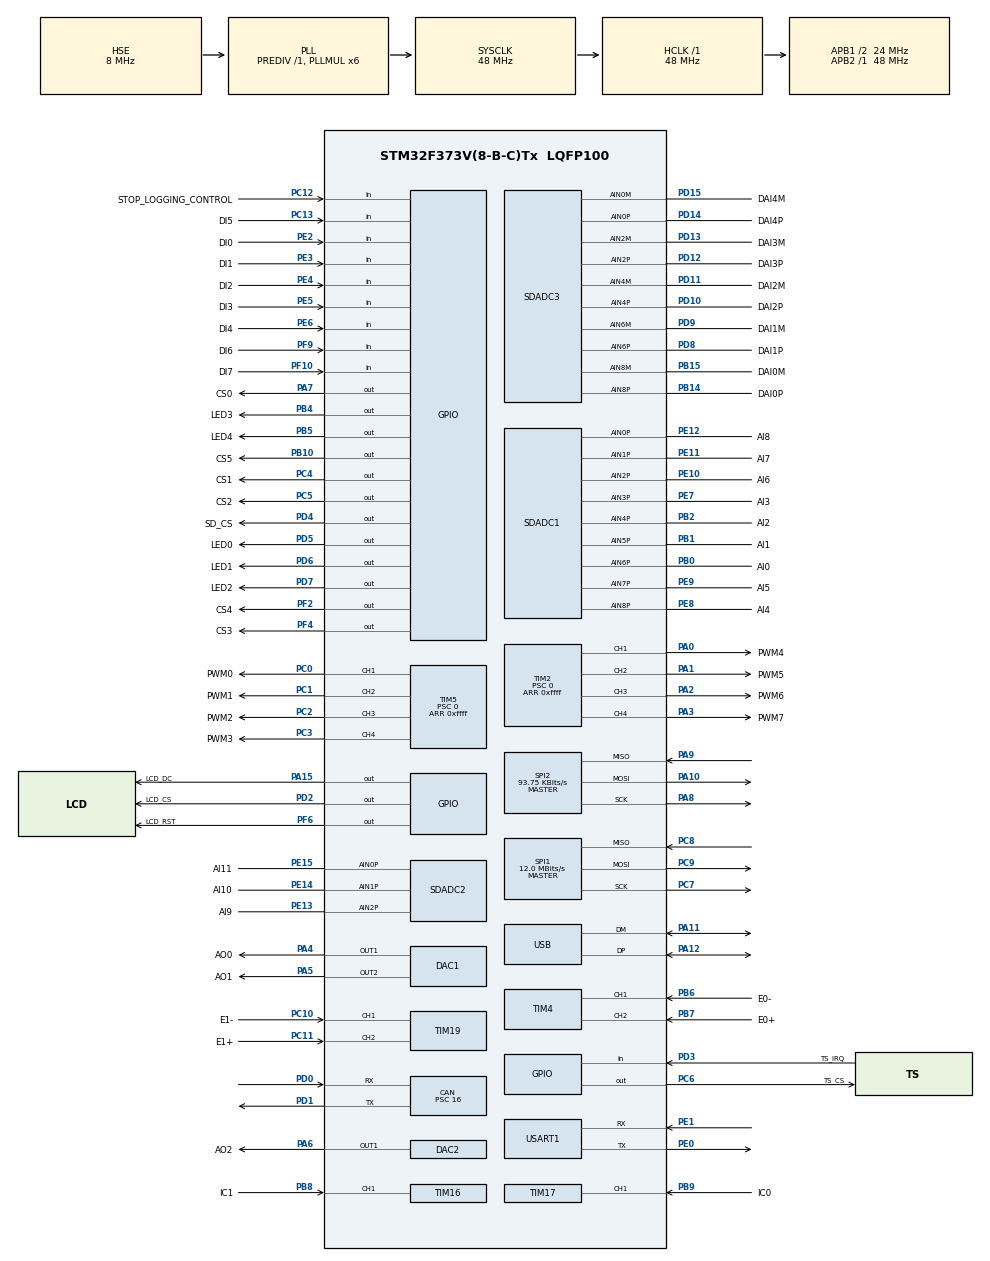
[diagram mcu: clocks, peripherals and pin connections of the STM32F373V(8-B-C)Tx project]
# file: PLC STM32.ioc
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CAN.BS1=CAN_BS1_3TQ
CAN.BS2=CAN_BS2_2TQ
CAN.CalculateBaudRate=250000
CAN.CalculateTimeBit=3999.99
CAN.CalculateTimeQuantum=666.6666666666666
CAN.Mode=CAN_MODE_NORMAL
CAN.Prescaler=16
CAN.SJW=CAN_SJW_1TQ
DAC1.DAC_OutputBuffer=DAC_OUTPUTBUFFER_ENABLE
DAC1.DAC_OutputBuffer2=DAC_OUTPUTBUFFER_ENABLE
DAC1.DAC_Trigger=DAC_TRIGGER_T6_TRGO
DAC1.DAC_Trigger2=DAC_TRIGGER_T6_TRGO
DAC2.DAC_OutputBuffer=DAC_OUTPUTBUFFER_ENABLE
DAC2.DAC_Trigger=DAC_TRIGGER_T6_TRGO
Dma.Request0=TIM17_CH1/UP
Dma.Request1=TIM16_CH1/UP
Dma.Request2=SDADC3
Dma.Request3=SDADC2
Dma.Request4=SDADC1
Dma.SDADC1.4.Direction=DMA_PERIPH_TO_MEMORY
Dma.SDADC1.4.Instance=DMA2_Channel3
Dma.SDADC1.4.MemDataAlignment=DMA_MDATAALIGN_HALFWORD
Dma.SDADC1.4.MemInc=DMA_MINC_ENABLE
Dma.SDADC1.4.Mode=DMA_CIRCULAR
Dma.SDADC1.4.PeriphDataAlignment=DMA_PDATAALIGN_HALFWORD
Dma.SDADC1.4.PeriphInc=DMA_PINC_DISABLE
Dma.SDADC1.4.Priority=DMA_PRIORITY_LOW
Dma.SDADC2.3.Direction=DMA_PERIPH_TO_MEMORY
Dma.SDADC2.3.Instance=DMA2_Channel4
Dma.SDADC2.3.MemDataAlignment=DMA_MDATAALIGN_HALFWORD
Dma.SDADC2.3.MemInc=DMA_MINC_ENABLE
Dma.SDADC2.3.Mode=DMA_CIRCULAR
Dma.SDADC2.3.PeriphDataAlignment=DMA_PDATAALIGN_HALFWORD
Dma.SDADC2.3.PeriphInc=DMA_PINC_DISABLE
Dma.SDADC2.3.Priority=DMA_PRIORITY_LOW
Dma.SDADC3.2.Direction=DMA_PERIPH_TO_MEMORY
Dma.SDADC3.2.Instance=DMA2_Channel5
Dma.SDADC3.2.MemDataAlignment=DMA_MDATAALIGN_HALFWORD
Dma.SDADC3.2.MemInc=DMA_MINC_ENABLE
Dma.SDADC3.2.Mode=DMA_CIRCULAR
Dma.SDADC3.2.PeriphDataAlignment=DMA_PDATAALIGN_HALFWORD
Dma.SDADC3.2.PeriphInc=DMA_PINC_DISABLE
Dma.SDADC3.2.Priority=DMA_PRIORITY_LOW
Dma.TIM16_CH1/UP.1.Direction=DMA_PERIPH_TO_MEMORY
Dma.TIM16_CH1/UP.1.Instance=DMA1_Channel3
Dma.TIM16_CH1/UP.1.MemDataAlignment=DMA_MDATAALIGN_HALFWORD
Dma.TIM16_CH1/UP.1.MemInc=DMA_MINC_ENABLE
Dma.TIM16_CH1/UP.1.Mode=DMA_CIRCULAR
Dma.TIM16_CH1/UP.1.PeriphDataAlignment=DMA_PDATAALIGN_HALFWORD
Dma.TIM16_CH1/UP.1.PeriphInc=DMA_PINC_DISABLE
Dma.TIM16_CH1/UP.1.Priority=DMA_PRIORITY_LOW
Dma.TIM17_CH1/UP.0.Direction=DMA_PERIPH_TO_MEMORY
Dma.TIM17_CH1/UP.0.Instance=DMA1_Channel1
Dma.TIM17_CH1/UP.0.MemDataAlignment=DMA_MDATAALIGN_HALFWORD
Dma.TIM17_CH1/UP.0.MemInc=DMA_MINC_ENABLE
Dma.TIM17_CH1/UP.0.Mode=DMA_CIRCULAR
Dma.TIM17_CH1/UP.0.PeriphDataAlignment=DMA_PDATAALIGN_HALFWORD
Dma.TIM17_CH1/UP.0.PeriphInc=DMA_PINC_DISABLE
Dma.TIM17_CH1/UP.0.Priority=DMA_PRIORITY_MEDIUM
FATFS._MAX_SS=512
FATFS._USE_LFN=0
Mcu.Family=STM32F3
Mcu.Name=STM32F373V(8-B-C)Tx
Mcu.Package=LQFP100
NVIC.CAN_RX0_IRQn=true\:0\:0\:true\:false\:true\:true\:true
NVIC.DMA1_Channel1_IRQn=true\:0\:0\:false\:false\:true\:false\:true
NVIC.DMA1_Channel3_IRQn=true\:0\:0\:false\:false\:true\:false\:true
NVIC.DMA2_Channel3_IRQn=true\:0\:0\:false\:false\:true\:false\:true
NVIC.DMA2_Channel4_IRQn=true\:0\:0\:false\:false\:true\:false\:true
NVIC.DMA2_Channel5_IRQn=true\:0\:0\:false\:false\:true\:false\:true
NVIC.PriorityGroup=NVIC_PRIORITYGROUP_4
NVIC.USB_LP_IRQn=true\:0\:0\:false\:false\:true\:false\:true
PA0.GPIO_Label=PWM4
PA0.Signal=S_TIM2_CH1_ETR
PA1.GPIO_Label=PWM5
PA1.Signal=S_TIM2_CH2
PA10.Mode=Full_Duplex_Master
PA10.Signal=SPI2_MOSI
PA11.Mode=Device
PA11.Signal=USB_DM
PA12.Mode=Device
PA12.Signal=USB_DP
PA13.Mode=Trace_Asynchronous_SW
PA13.Signal=SYS_JTMS-SWDIO
PA14.Mode=Trace_Asynchronous_SW
PA14.Signal=SYS_JTCK-SWCLK
PA15.GPIO_Label=LCD_DC
PA15.Signal=GPIO_Output
PA2.GPIO_Label=PWM6
PA2.Signal=S_TIM2_CH3
PA3.GPIO_Label=PWM7
PA3.Signal=S_TIM2_CH4
PA4.GPIO_Label=AO0
PA4.Signal=COMP_DAC11_group
PA5.GPIO_Label=AO1
PA5.Signal=COMP_DAC12_group
PA6.GPIO_Label=AO2
PA6.Signal=COMP_DAC21_group
PA7.GPIO_Label=CS0
PA7.GPIO_PuPd=GPIO_PULLUP
PA7.PinState=GPIO_PIN_SET
PA7.Signal=GPIO_Output
PA8.Mode=Full_Duplex_Master
PA8.Signal=SPI2_SCK
PA9.Mode=Full_Duplex_Master
PA9.Signal=SPI2_MISO
PB0.GPIO_Label=AI0
PB0.Mode=IN6-Single-Ended zero reference
PB0.Signal=SDADC1_AIN6P
PB1.GPIO_Label=AI1
PB1.Mode=IN5-Single-Ended zero reference
PB1.Signal=SDADC1_AIN5P
PB10.GPIO_Label=CS5
PB10.GPIO_PuPd=GPIO_PULLUP
PB10.PinState=GPIO_PIN_SET
PB10.Signal=GPIO_Output
PB14.GPIO_Label=DAI0P
PB14.Mode=IN8-Differential
PB14.Signal=SDADC3_AIN8P
PB15.GPIO_Label=DAI0M
PB15.Mode=IN8-Differential
PB15.Signal=SDADC3_AIN8M
PB2.GPIO_Label=AI2
PB2.Mode=IN4-Single-Ended zero reference
PB2.Signal=SDADC1_AIN4P
PB3.Mode=Trace_Asynchronous_SW
PB3.Signal=SYS_JTDO-TRACESWO
PB4.GPIO_Label=LED3
PB4.Signal=GPIO_Output
PB5.GPIO_Label=LED4
PB5.Signal=GPIO_Output
PB6.GPIO_Label=E0-
PB6.Signal=S_TIM4_CH1
PB7.GPIO_Label=E0+
PB7.Signal=S_TIM4_CH2
PB8.GPIO_Label=IC1
PB8.Signal=S_TIM16_CH1
PB9.GPIO_Label=IC0
PB9.Signal=S_TIM17_CH1
PC0.GPIO_Label=PWM0
PC0.Signal=S_TIM5_CH1_ETR
PC1.GPIO_Label=PWM1
PC1.Signal=S_TIM5_CH2
PC10.GPIO_Label=E1-
PC10.Signal=S_TIM19_CH1
PC11.GPIO_Label=E1+
PC11.Signal=S_TIM19_CH2
PC12.GPIO_Label=STOP_LOGGING_CONTROL
PC12.Signal=GPIO_Input
PC13.GPIO_Label=DI5
PC13.Signal=GPIO_Input
PC14-OSC32_IN.Mode=LSE-External-Oscillator
PC14-OSC32_IN.Signal=RCC_OSC32_IN
PC15-OSC32_OUT.Mode=LSE-External-Oscillator
PC15-OSC32_OUT.Signal=RCC_OSC32_OUT
PC2.GPIO_Label=PWM2
PC2.Signal=S_TIM5_CH3
PC3.GPIO_Label=PWM3
PC3.Signal=S_TIM5_CH4
PC4.GPIO_Label=CS1
PC4.GPIO_PuPd=GPIO_PULLUP
PC4.PinState=GPIO_PIN_SET
PC4.Signal=GPIO_Output
PC5.GPIO_Label=CS2
PC5.GPIO_PuPd=GPIO_PULLUP
PC5.PinState=GPIO_PIN_SET
PC5.Signal=GPIO_Output
PC6.GPIO_Label=TS_CS
PC6.GPIO_PuPd=GPIO_PULLUP
PC6.PinState=GPIO_PIN_SET
PC6.Signal=GPIO_Output
PC7.Mode=Full_Duplex_Master
PC7.Signal=SPI1_SCK
PC8.Mode=Full_Duplex_Master
PC8.Signal=SPI1_MISO
PC9.Mode=Full_Duplex_Master
PC9.Signal=SPI1_MOSI
PD0.Mode=CAN_Activate
PD0.Signal=CAN_RX
PD1.Mode=CAN_Activate
PD1.Signal=CAN_TX
PD10.GPIO_Label=DAI2P
PD10.Mode=IN4-Differential
PD10.Signal=SDADC3_AIN4P
PD11.GPIO_Label=DAI2M
PD11.Mode=IN4-Differential
PD11.Signal=SDADC3_AIN4M
PD12.GPIO_Label=DAI3P
PD12.Mode=IN2-Differential
PD12.Signal=SDADC3_AIN2P
PD13.GPIO_Label=DAI3M
PD13.Mode=IN2-Differential
PD13.Signal=SDADC3_AIN2M
PD14.GPIO_Label=DAI4P
PD14.Mode=IN0-Differential
PD14.Signal=SDADC3_AIN0P
PD15.GPIO_Label=DAI4M
PD15.Mode=IN0-Differential
PD15.Signal=SDADC3_AIN0M
PD2.GPIO_Label=LCD_CS
PD2.GPIO_PuPd=GPIO_PULLUP
PD2.PinState=GPIO_PIN_SET
PD2.Signal=GPIO_Output
PD3.GPIO_Label=TS_IRQ
PD3.GPIO_PuPd=GPIO_PULLUP
PD3.Signal=GPIO_Input
PD4.GPIO_Label=SD_CS
PD4.GPIO_PuPd=GPIO_PULLUP
PD4.PinState=GPIO_PIN_SET
PD4.Signal=GPIO_Output
PD5.GPIO_Label=LED0
PD5.Signal=GPIO_Output
PD6.GPIO_Label=LED1
PD6.Signal=GPIO_Output
PD7.GPIO_Label=LED2
PD7.Signal=GPIO_Output
PD8.GPIO_Label=DAI1P
PD8.Mode=IN6-Differential
PD8.Signal=SDADC3_AIN6P
PD9.GPIO_Label=DAI1M
PD9.Mode=IN6-Differential
PD9.Signal=SDADC3_AIN6M
PE0.Mode=Asynchronous
PE0.Signal=USART1_TX
PE1.Mode=Asynchronous
PE1.Signal=USART1_RX
PE10.GPIO_Label=AI6
PE10.Mode=IN2-Single-Ended zero reference
PE10.Signal=SDADC1_AIN2P
PE11.GPIO_Label=AI7
PE11.Mode=IN1-Single-Ended zero reference
PE11.Signal=SDADC1_AIN1P
PE12.GPIO_Label=AI8
PE12.Mode=IN0-Single-Ended zero reference
PE12.Signal=SDADC1_AIN0P
PE13.GPIO_Label=AI9
PE13.Mode=IN2-Single-Ended zero reference
PE13.Signal=SDADC2_AIN2P
PE14.GPIO_Label=AI10
PE14.Mode=IN1-Single-Ended zero reference
PE14.Signal=SDADC2_AIN1P
PE15.GPIO_Label=AI11
PE15.Mode=IN0-Single-Ended zero reference
PE15.Signal=SDADC2_AIN0P
PE2.GPIO_Label=DI0
PE2.Signal=GPIO_Input
PE3.GPIO_Label=DI1
PE3.Signal=GPIO_Input
PE4.GPIO_Label=DI2
PE4.Signal=GPIO_Input
PE5.GPIO_Label=DI3
PE5.Signal=GPIO_Input
PE6.GPIO_Label=DI4
PE6.Signal=GPIO_Input
PE7.GPIO_Label=AI3
PE7.Mode=IN3-Single-Ended zero reference
PE7.Signal=SDADC1_AIN3P
PE8.GPIO_Label=AI4
PE8.Mode=IN8-Single-Ended zero reference
PE8.Signal=SDADC1_AIN8P
PE9.GPIO_Label=AI5
PE9.Mode=IN7-Single-Ended zero reference
PE9.Signal=SDADC1_AIN7P
PF0-OSC_IN.Mode=HSE-External-Oscillator
PF0-OSC_IN.Signal=RCC_OSC_IN
PF1-OSC_OUT.Mode=HSE-External-Oscillator
PF1-OSC_OUT.Signal=RCC_OSC_OUT
PF10.GPIO_Label=DI7
PF10.Signal=GPIO_Input
PF2.GPIO_Label=CS4
PF2.GPIO_ModeDefaultOutputPP=GPIO_MODE_OUTPUT_PP
PF2.GPIO_PuPd=GPIO_PULLUP
PF2.PinState=GPIO_PIN_SET
PF2.Signal=GPIO_Output
PF4.GPIO_Label=CS3
PF4.Signal=GPIO_Output
PF6.GPIO_Label=LCD_RST
PF6.Signal=GPIO_Output
PF9.GPIO_Label=DI6
PF9.Signal=GPIO_Input
ProjectManager.HeapSize=0x200
ProjectManager.StackSize=0x400
ProjectManager.TargetToolchain=STM32CubeIDE
RCC.AHBFreq_Value=48000000
RCC.APB1CLKDivider=RCC_HCLK_DIV2
RCC.APB1Freq_Value=24000000
RCC.APB1TimFreq_Value=48000000
RCC.APB2Freq_Value=48000000
RCC.APB2TimFreq_Value=48000000
RCC.CortexFreq_Value=48000000
RCC.HCLKFreq_Value=48000000
RCC.HSE_VALUE=8000000
RCC.HSI_VALUE=8000000
RCC.PLLMUL=RCC_PLL_MUL6
RCC.SDADCPresc=RCC_SDADCSYSCLK_DIV8
RCC.SYSCLKFreq_VALUE=48000000
RCC.SYSCLKSource=RCC_SYSCLKSOURCE_PLLCLK
RCC.USBFreq_Value=48000000
RTC.Alarm-Alarm\ A=RTC_ALARM_A
RTC.AlarmDateWeekDaySel-Alarm\ A=RTC_ALARMDATEWEEKDAYSEL_DATE
RTC.AlarmDateWeekDaySel_B-Alarm\ B=RTC_ALARMDATEWEEKDAYSEL_WEEKDAY
RTC.Alarm_B-Alarm\ B=RTC_ALARM_B
RTC.Format=RTC_FORMAT_BIN
SDADC1.CommonMode0=SDADC_COMMON_MODE_VSSA
SDADC1.EnableInjectedConversion=ENABLE
SDADC1.EnableRegularconversion=DISABLE
SDADC1.Gain1=SDADC_GAIN_1
SDADC1.Gain2=SDADC_GAIN_1
SDADC1.InjDelay=Disable
SDADC1.InjNumberOfConversion=9
SDADC1.InjectedChannel-11\#ChannelInjectedConversion=SDADC_CHANNEL_0
SDADC1.InjectedChannel-20\#ChannelInjectedConversion=SDADC_CHANNEL_1
SDADC1.InjectedChannel-21\#ChannelInjectedConversion=SDADC_CHANNEL_2
SDADC1.InjectedChannel-22\#ChannelInjectedConversion=SDADC_CHANNEL_3
SDADC1.InjectedChannel-23\#ChannelInjectedConversion=SDADC_CHANNEL_4
SDADC1.InjectedChannel-24\#ChannelInjectedConversion=SDADC_CHANNEL_5
SDADC1.InjectedChannel-25\#ChannelInjectedConversion=SDADC_CHANNEL_6
SDADC1.InjectedChannel-26\#ChannelInjectedConversion=SDADC_CHANNEL_7
SDADC1.InjectedChannel-27\#ChannelInjectedConversion=SDADC_CHANNEL_8
SDADC1.InjectedChannelsSelection=SDADC_CHANNEL_0|SDADC_CHANNEL_1|SDADC_CHANNEL_2|SDADC_CHANNEL_3|SDADC_CHANNEL_4|SDADC_CHANNEL_5|SDADC_CHANNEL_6|SDADC_CHANNEL_7|SDADC_CHANNEL_8
SDADC1.InjectedConfIndex-11\#ChannelInjectedConversion=SDADC_CONF_INDEX_0
SDADC1.InjectedConfIndex-20\#ChannelInjectedConversion=SDADC_CONF_INDEX_0
SDADC1.InjectedConfIndex-21\#ChannelInjectedConversion=SDADC_CONF_INDEX_0
SDADC1.InjectedConfIndex-22\#ChannelInjectedConversion=SDADC_CONF_INDEX_1
SDADC1.InjectedConfIndex-23\#ChannelInjectedConversion=SDADC_CONF_INDEX_1
SDADC1.InjectedConfIndex-24\#ChannelInjectedConversion=SDADC_CONF_INDEX_1
SDADC1.InjectedConfIndex-25\#ChannelInjectedConversion=SDADC_CONF_INDEX_2
SDADC1.InjectedConfIndex-26\#ChannelInjectedConversion=SDADC_CONF_INDEX_2
SDADC1.InjectedConfIndex-27\#ChannelInjectedConversion=SDADC_CONF_INDEX_2
SDADC1.InjectedContinuousMode=SDADC_CONTINUOUS_CONV_ON
SDADC1.InjectedRank-11\#ChannelInjectedConversion=1
SDADC1.InjectedRank-20\#ChannelInjectedConversion=2
SDADC1.InjectedRank-21\#ChannelInjectedConversion=3
SDADC1.InjectedRank-22\#ChannelInjectedConversion=4
SDADC1.InjectedRank-23\#ChannelInjectedConversion=5
SDADC1.InjectedRank-24\#ChannelInjectedConversion=6
SDADC1.InjectedRank-25\#ChannelInjectedConversion=7
SDADC1.InjectedRank-26\#ChannelInjectedConversion=8
SDADC1.InjectedRank-27\#ChannelInjectedConversion=9
SDADC1.InjectedTrigger=SDADC_EXTERNAL_TRIGGER
SDADC1.InputMode0=SDADC_INPUT_MODE_SE_ZERO_REFERENCE
SDADC1.InputMode1=SDADC_INPUT_MODE_SE_ZERO_REFERENCE
SDADC1.InputMode2=SDADC_INPUT_MODE_SE_ZERO_REFERENCE
SDADC1.NbrOfConversionFlag=1
SDADC2.EnableInjectedConversion=ENABLE
SDADC2.EnableRegularconversion=DISABLE
SDADC2.InjDelay=Disable
SDADC2.InjNumberOfConversion=3
SDADC2.InjectedChannel-0\#ChannelInjectedConversion=SDADC_CHANNEL_0
SDADC2.InjectedChannel-3\#ChannelInjectedConversion=SDADC_CHANNEL_1
SDADC2.InjectedChannel-4\#ChannelInjectedConversion=SDADC_CHANNEL_2
SDADC2.InjectedChannelsSelection=SDADC_CHANNEL_0|SDADC_CHANNEL_1|SDADC_CHANNEL_2
SDADC2.InjectedConfIndex-0\#ChannelInjectedConversion=SDADC_CONF_INDEX_0
SDADC2.InjectedConfIndex-3\#ChannelInjectedConversion=SDADC_CONF_INDEX_1
SDADC2.InjectedConfIndex-4\#ChannelInjectedConversion=SDADC_CONF_INDEX_2
SDADC2.InjectedContinuousMode=SDADC_CONTINUOUS_CONV_ON
SDADC2.InjectedExtTrigger=SDADC_EXT_TRIG_TIM12_CC1
SDADC2.InjectedRank-0\#ChannelInjectedConversion=1
SDADC2.InjectedRank-3\#ChannelInjectedConversion=2
SDADC2.InjectedRank-4\#ChannelInjectedConversion=3
SDADC2.InjectedTrigger=SDADC_EXTERNAL_TRIGGER
SDADC2.InputMode0=SDADC_INPUT_MODE_SE_ZERO_REFERENCE
SDADC2.InputMode1=SDADC_INPUT_MODE_SE_ZERO_REFERENCE
SDADC2.InputMode2=SDADC_INPUT_MODE_SE_ZERO_REFERENCE
SDADC2.NbrOfConversionFlag=1
SDADC3.EnableInjectedConversion=ENABLE
SDADC3.EnableRegularconversion=DISABLE
SDADC3.InjDelay=Disable
SDADC3.InjNumberOfConversion=5
SDADC3.InjectedChannel-0\#ChannelInjectedConversion=SDADC_CHANNEL_0
SDADC3.InjectedChannel-5\#ChannelInjectedConversion=SDADC_CHANNEL_2
SDADC3.InjectedChannel-6\#ChannelInjectedConversion=SDADC_CHANNEL_4
SDADC3.InjectedChannel-7\#ChannelInjectedConversion=SDADC_CHANNEL_6
SDADC3.InjectedChannel-8\#ChannelInjectedConversion=SDADC_CHANNEL_8
SDADC3.InjectedChannelsSelection=SDADC_CHANNEL_0|SDADC_CHANNEL_2|SDADC_CHANNEL_4|SDADC_CHANNEL_6|SDADC_CHANNEL_8
SDADC3.InjectedConfIndex-0\#ChannelInjectedConversion=SDADC_CONF_INDEX_0
SDADC3.InjectedConfIndex-5\#ChannelInjectedConversion=SDADC_CONF_INDEX_0
SDADC3.InjectedConfIndex-6\#ChannelInjectedConversion=SDADC_CONF_INDEX_1
SDADC3.InjectedConfIndex-7\#ChannelInjectedConversion=SDADC_CONF_INDEX_1
SDADC3.InjectedConfIndex-8\#ChannelInjectedConversion=SDADC_CONF_INDEX_2
SDADC3.InjectedContinuousMode=SDADC_CONTINUOUS_CONV_ON
SDADC3.InjectedExtTrigger=SDADC_EXT_TRIG_TIM12_CC2
SDADC3.InjectedRank-0\#ChannelInjectedConversion=1
SDADC3.InjectedRank-5\#ChannelInjectedConversion=2
SDADC3.InjectedRank-6\#ChannelInjectedConversion=3
SDADC3.InjectedRank-7\#ChannelInjectedConversion=4
SDADC3.InjectedRank-8\#ChannelInjectedConversion=5
SDADC3.InjectedTrigger=SDADC_EXTERNAL_TRIGGER
SDADC3.NbrOfConversionFlag=1
SH.COMP_DAC11_group.0=DAC1_OUT1,DAC_OUT1
SH.COMP_DAC12_group.0=DAC1_OUT2,Enable_DAC_OUT2
SH.COMP_DAC21_group.0=DAC2_OUT1,DAC_OUT1
SH.S_TIM16_CH1.0=TIM16_CH1,Input_Capture1_from_TI1
SH.S_TIM17_CH1.0=TIM17_CH1,Input_Capture1_from_TI1
SH.S_TIM19_CH1.0=TIM19_CH1,Encoder_Interface
SH.S_TIM19_CH2.0=TIM19_CH2,Encoder_Interface
SH.S_TIM2_CH1_ETR.0=TIM2_CH1,PWM Generation1 CH1
SH.S_TIM2_CH2.0=TIM2_CH2,PWM Generation2 CH2
SH.S_TIM2_CH3.0=TIM2_CH3,PWM Generation3 CH3
SH.S_TIM2_CH4.0=TIM2_CH4,PWM Generation4 CH4
SH.S_TIM4_CH1.0=TIM4_CH1,Encoder_Interface
SH.S_TIM4_CH2.0=TIM4_CH2,Encoder_Interface
SH.S_TIM5_CH1_ETR.0=TIM5_CH1,PWM Generation1 CH1
SH.S_TIM5_CH2.0=TIM5_CH2,PWM Generation2 CH2
SH.S_TIM5_CH3.0=TIM5_CH3,PWM Generation3 CH3
SH.S_TIM5_CH4.0=TIM5_CH4,PWM Generation4 CH4
SPI1.BaudRatePrescaler=SPI_BAUDRATEPRESCALER_4
SPI1.CalculateBaudRate=12.0 MBits/s
SPI1.DataSize=SPI_DATASIZE_8BIT
SPI1.Direction=SPI_DIRECTION_2LINES
SPI1.Mode=SPI_MODE_MASTER
SPI1.VirtualType=VM_MASTER
SPI2.BaudRatePrescaler=SPI_BAUDRATEPRESCALER_256
SPI2.CLKPhase=SPI_PHASE_1EDGE
SPI2.CLKPolarity=SPI_POLARITY_LOW
SPI2.CalculateBaudRate=93.75 KBits/s
SPI2.DataSize=SPI_DATASIZE_8BIT
SPI2.Direction=SPI_DIRECTION_2LINES
SPI2.Mode=SPI_MODE_MASTER
SPI2.VirtualType=VM_MASTER
TIM12.Channel-Output\ Compare1\ No\ Output=TIM_CHANNEL_1
TIM12.Channel-Output\ Compare2\ No\ Output=TIM_CHANNEL_2
TIM12.OCMode_1=TIM_OCMODE_TOGGLE
TIM12.Period=0xbb80
TIM12.Prescaler=0
TIM12.Pulse-Output\ Compare1\ No\ Output=0
TIM13.Channel=TIM_CHANNEL_1
TIM13.OCMode_1=TIM_OCMODE_TOGGLE
TIM13.Period=0xbb80
TIM13.Prescaler=0
TIM13.Pulse=0
TIM16.Channel=TIM_CHANNEL_1
TIM16.Period=0xffff
TIM16.Prescaler=4799
TIM17.Channel=TIM_CHANNEL_1
TIM17.Period=0xffff
TIM17.Prescaler=4799
TIM19.EncoderMode=TIM_ENCODERMODE_TI12
TIM2.Channel-PWM\ Generation1\ CH1=TIM_CHANNEL_1
TIM2.Channel-PWM\ Generation2\ CH2=TIM_CHANNEL_2
TIM2.Channel-PWM\ Generation3\ CH3=TIM_CHANNEL_3
TIM2.Channel-PWM\ Generation4\ CH4=TIM_CHANNEL_4
TIM2.Period=0xffff
TIM2.Prescaler=0
TIM2.Pulse-PWM\ Generation4\ CH4=0
TIM4.EncoderMode=TIM_ENCODERMODE_TI12
TIM5.Channel-PWM\ Generation1\ CH1=TIM_CHANNEL_1
TIM5.Channel-PWM\ Generation2\ CH2=TIM_CHANNEL_2
TIM5.Channel-PWM\ Generation3\ CH3=TIM_CHANNEL_3
TIM5.Channel-PWM\ Generation4\ CH4=TIM_CHANNEL_4
TIM5.Period=0xffff
TIM5.Prescaler=0
TIM5.Pulse-PWM\ Generation4\ CH4=0
TIM6.Period=0xbb80
TIM6.Prescaler=99
TIM6.TIM_MasterOutputTrigger=TIM_TRGO_UPDATE
USART1.VirtualMode-Asynchronous=VM_ASYNC
USB_DEVICE.CLASS_NAME_FS=CDC
USB_DEVICE.PRODUCT_STRING_CDC_FS=STM32 Virtual ComPort
USB_DEVICE.USBD_SELF_POWERED=0
USB_DEVICE.VirtualMode=Cdc
USB_DEVICE.VirtualModeFS=Cdc_FS
VP_FATFS_VS_Generic.Mode=User_defined
VP_RTC_VS_RTC_Activate.Mode=RTC_Enabled
VP_RTC_VS_RTC_Alarm_A_Intern.Mode=Alarm A
VP_RTC_VS_RTC_Alarm_B_Intern.Mode=Alarm B
VP_RTC_VS_RTC_Calendar.Mode=RTC_Calendar
VP_SDADC1_CONF0.Mode=ConfigZero
VP_SDADC1_CONF1.Mode=ConfigUn
VP_SDADC1_CONF2.Mode=ConfigDeux
VP_SDADC2_CONF0.Mode=ConfigZero
VP_SDADC2_CONF1.Mode=ConfigUn
VP_SDADC2_CONF2.Mode=ConfigDeux
VP_SDADC3_CONF0.Mode=ConfigZero
VP_SDADC3_CONF1.Mode=ConfigUn
VP_SDADC3_CONF2.Mode=ConfigDeux
VP_TIM12_VS_ClockSourceINT.Mode=Internal
VP_TIM12_VS_no_output1.Mode=Output Compare1 No Output
VP_TIM12_VS_no_output2.Mode=Output Compare2 No Output
VP_TIM13_VS_ClockSourceINT.Mode=Enable_Timer
VP_TIM13_VS_no_output1.Mode=Output Compare1 No Output
VP_TIM16_VS_ClockSourceINT.Mode=Enable_Timer
VP_TIM17_VS_ClockSourceINT.Mode=Enable_Timer
VP_TIM2_VS_ClockSourceINT.Mode=Internal
VP_TIM5_VS_ClockSourceINT.Mode=Internal
VP_TIM6_VS_ClockSourceINT.Mode=Enable_Timer
VP_USB_DEVICE_VS_USB_DEVICE_CDC_FS.Mode=CDC_FS
board=custom

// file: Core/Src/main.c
/* USER CODE BEGIN Header */
/**
  ******************************************************************************
  * @file           : main.c
  * @brief          : Main program body
  ******************************************************************************
  * @attention
  *
  * <h2><center>&copy; Copyright (c) 2021 STMicroelectronics.
  * All rights reserved.</center></h2>
  *
  * This software component is licensed by ST under BSD 3-Clause license,
  * the "License"; You may not use this file except in compliance with the
  * License. You may obtain a copy of the License at:
  *                        opensource.org/licenses/BSD-3-Clause
  *
  ******************************************************************************
  */
/* USER CODE END Header */
#include "main.h"
#include "fatfs.h"
#include "usb_device.h"

/* USER CODE BEGIN Includes */
#include "STM32 PLC/Functions.h"
/* USER CODE END Includes */

CAN_HandleTypeDef hcan;

DAC_HandleTypeDef hdac1;
DAC_HandleTypeDef hdac2;

RTC_HandleTypeDef hrtc;

SDADC_HandleTypeDef hsdadc1;
SDADC_HandleTypeDef hsdadc2;
SDADC_HandleTypeDef hsdadc3;
DMA_HandleTypeDef hdma_sdadc1;
DMA_HandleTypeDef hdma_sdadc2;
DMA_HandleTypeDef hdma_sdadc3;

SPI_HandleTypeDef hspi1;
SPI_HandleTypeDef hspi2;

TIM_HandleTypeDef htim2;
TIM_HandleTypeDef htim4;
TIM_HandleTypeDef htim5;
TIM_HandleTypeDef htim6;
TIM_HandleTypeDef htim12;
TIM_HandleTypeDef htim13;
TIM_HandleTypeDef htim16;
TIM_HandleTypeDef htim17;
TIM_HandleTypeDef htim19;
DMA_HandleTypeDef hdma_tim16_ch1_up;
DMA_HandleTypeDef hdma_tim17_ch1_up;

UART_HandleTypeDef huart1;

void SystemClock_Config(void);
static void MX_GPIO_Init(void);
static void MX_DAC1_Init(void);
static void MX_DAC2_Init(void);
static void MX_RTC_Init(void);
static void MX_SPI2_Init(void);
static void MX_TIM2_Init(void);
static void MX_TIM5_Init(void);
static void MX_SPI1_Init(void);
static void MX_TIM4_Init(void);
static void MX_SDADC1_Init(void);
static void MX_SDADC2_Init(void);
static void MX_SDADC3_Init(void);
static void MX_CAN_Init(void);
static void MX_USART1_UART_Init(void);
static void MX_TIM6_Init(void);
static void MX_TIM12_Init(void);
static void MX_TIM13_Init(void);
static void MX_TIM16_Init(void);
static void MX_TIM17_Init(void);
static void MX_DMA_Init(void);
static void MX_TIM19_Init(void);

int main(void)
{

  /* MCU Configuration--------------------------------------------------------*/

  /* Reset of all peripherals, Initializes the Flash interface and the Systick. */
  HAL_Init();

  /* Configure the system clock */
  SystemClock_Config();

  /* Initialize all configured peripherals */
  MX_GPIO_Init();
  MX_DAC1_Init();
  MX_DAC2_Init();
  MX_RTC_Init();
  MX_SPI2_Init();
  MX_TIM2_Init();
  MX_TIM5_Init();
  MX_SPI1_Init();
  MX_TIM4_Init();
  MX_SDADC1_Init();
  MX_SDADC2_Init();
  MX_SDADC3_Init();
  MX_CAN_Init();
  MX_USART1_UART_Init();
  MX_TIM6_Init();
  MX_TIM12_Init();
  MX_TIM13_Init();
  MX_TIM16_Init();
  MX_USB_DEVICE_Init();
  MX_FATFS_Init();
  MX_TIM17_Init();
  MX_DMA_Init();
  MX_TIM19_Init();
  /* USER CODE BEGIN 2 */

  /* SAE J1939 */
  J1939 j1939 = {0};
  for(uint8_t i = 0; i < 0xFF; i++)
	  j1939.ECU_address[i] = 0xFF;

  /* Start */
  STM32_PLC_Start_Analog_Input(&htim12, &htim13, &hsdadc1, &hsdadc2, &hsdadc3);
  STM32_PLC_Start_Analog_Output(&hdac1, &hdac2, &htim6);
  STM32_PLC_Start_Encoder(&htim4, &htim19);
  STM32_PLC_Start_Input_Capture(&htim17, &htim16);
  STM32_PLC_Start_PWM(&htim2, &htim5);
  STM32_PLC_Start_SD(&hspi2, SD_CS_GPIO_Port, SD_CS_Pin);
  STM32_PLC_Start_RTC(&hrtc);
  STM32_PLC_Start_CAN(&hcan, &j1939);
  STM32_PLC_Start_LCD(&hspi1, &hspi2, LCD_CS_GPIO_Port, LCD_CS_Pin, LCD_DC_GPIO_Port, LCD_DC_Pin, LCD_RST_GPIO_Port, LCD_RST_Pin, TS_CS_GPIO_Port, TS_CS_Pin);

  /* Reset outputs */
  STM32_PLC_PWM_Reset();
  STM32_PLC_Analog_Output_Reset();

  /* If we are going to send and receive the ECU identification and component identification, we need to specify the size of them */
  j1939.this_identifications.ecu_identification.length_of_each_field = 30;
  j1939.this_identifications.component_identification.length_of_each_field = 30;
  j1939.from_other_ecu_identifications.ecu_identification.length_of_each_field = 30;
  j1939.from_other_ecu_identifications.component_identification.length_of_each_field = 30;

  /* LCD */
  //STM32_PLC_LCD_Show_Intro_Frame();
  uint8_t frame_id = 0;
  STM32_PLC_LCD_Show_Main_Frame(&frame_id, false);

  /* Mount SD card and read initial start up */
  STM32_PLC_Initial_Startup(&j1939);

  /* USER CODE END 2 */

  /* Infinite loop */
  while (1)
  {

    /* USER CODE BEGIN 3 */

	  /* Listen for frame changes */
	  STM32_PLC_LCD_Call_Main_Logic(&frame_id, &j1939);
	  /* Perform control program */
	  STM32_PLC_LCD_Execute_Control_Program(&j1939);

  }
  /* USER CODE END 3 */
}

void SystemClock_Config(void)
{
  RCC_OscInitTypeDef RCC_OscInitStruct = {0};
  RCC_ClkInitTypeDef RCC_ClkInitStruct = {0};
  RCC_PeriphCLKInitTypeDef PeriphClkInit = {0};

  /** Initializes the RCC Oscillators according to the specified parameters
  * in the RCC_OscInitTypeDef structure.
  */
  RCC_OscInitStruct.OscillatorType = RCC_OSCILLATORTYPE_LSI|RCC_OSCILLATORTYPE_HSE;
  RCC_OscInitStruct.HSEState = RCC_HSE_ON;
  RCC_OscInitStruct.HSEPredivValue = RCC_HSE_PREDIV_DIV1;
  RCC_OscInitStruct.HSIState = RCC_HSI_ON;
  RCC_OscInitStruct.LSIState = RCC_LSI_ON;
  RCC_OscInitStruct.PLL.PLLState = RCC_PLL_ON;
  RCC_OscInitStruct.PLL.PLLSource = RCC_PLLSOURCE_HSE;
  RCC_OscInitStruct.PLL.PLLMUL = RCC_PLL_MUL6;
  if (HAL_RCC_OscConfig(&RCC_OscInitStruct) != HAL_OK)
  {
    Error_Handler();
  }
  /** Initializes the CPU, AHB and APB buses clocks
  */
  RCC_ClkInitStruct.ClockType = RCC_CLOCKTYPE_HCLK|RCC_CLOCKTYPE_SYSCLK
                              |RCC_CLOCKTYPE_PCLK1|RCC_CLOCKTYPE_PCLK2;
  RCC_ClkInitStruct.SYSCLKSource = RCC_SYSCLKSOURCE_PLLCLK;
  RCC_ClkInitStruct.AHBCLKDivider = RCC_SYSCLK_DIV1;
  RCC_ClkInitStruct.APB1CLKDivider = RCC_HCLK_DIV2;
  RCC_ClkInitStruct.APB2CLKDivider = RCC_HCLK_DIV1;

  if (HAL_RCC_ClockConfig(&RCC_ClkInitStruct, FLASH_LATENCY_1) != HAL_OK)
  {
    Error_Handler();
  }
  PeriphClkInit.PeriphClockSelection = RCC_PERIPHCLK_USB|RCC_PERIPHCLK_USART1
                              |RCC_PERIPHCLK_RTC|RCC_PERIPHCLK_SDADC;
  PeriphClkInit.Usart1ClockSelection = RCC_USART1CLKSOURCE_PCLK2;
  PeriphClkInit.RTCClockSelection = RCC_RTCCLKSOURCE_LSI;
  PeriphClkInit.USBClockSelection = RCC_USBCLKSOURCE_PLL;
  PeriphClkInit.SdadcClockSelection = RCC_SDADCSYSCLK_DIV8;
  if (HAL_RCCEx_PeriphCLKConfig(&PeriphClkInit) != HAL_OK)
  {
    Error_Handler();
  }
  HAL_PWREx_EnableSDADC(PWR_SDADC_ANALOG1);
  HAL_PWREx_EnableSDADC(PWR_SDADC_ANALOG2);
  HAL_PWREx_EnableSDADC(PWR_SDADC_ANALOG3);
}

static void MX_CAN_Init(void)
{

  hcan.Instance = CAN;
  hcan.Init.Prescaler = 16;
  hcan.Init.Mode = CAN_MODE_NORMAL;
  hcan.Init.SyncJumpWidth = CAN_SJW_1TQ;
  hcan.Init.TimeSeg1 = CAN_BS1_3TQ;
  hcan.Init.TimeSeg2 = CAN_BS2_2TQ;
  hcan.Init.TimeTriggeredMode = DISABLE;
  hcan.Init.AutoBusOff = DISABLE;
  hcan.Init.AutoWakeUp = DISABLE;
  hcan.Init.AutoRetransmission = DISABLE;
  hcan.Init.ReceiveFifoLocked = DISABLE;
  hcan.Init.TransmitFifoPriority = DISABLE;
  if (HAL_CAN_Init(&hcan) != HAL_OK)
  {
    Error_Handler();
  }

}

static void MX_DAC1_Init(void)
{

  DAC_ChannelConfTypeDef sConfig = {0};

  /** DAC Initialization
  */
  hdac1.Instance = DAC1;
  if (HAL_DAC_Init(&hdac1) != HAL_OK)
  {
    Error_Handler();
  }
  /** DAC channel OUT1 config
  */
  sConfig.DAC_Trigger = DAC_TRIGGER_T6_TRGO;
  sConfig.DAC_OutputBuffer = DAC_OUTPUTBUFFER_ENABLE;
  if (HAL_DAC_ConfigChannel(&hdac1, &sConfig, DAC_CHANNEL_1) != HAL_OK)
  {
    Error_Handler();
  }
  /** DAC channel OUT2 config
  */
  if (HAL_DAC_ConfigChannel(&hdac1, &sConfig, DAC_CHANNEL_2) != HAL_OK)
  {
    Error_Handler();
  }

}

static void MX_DAC2_Init(void)
{

  DAC_ChannelConfTypeDef sConfig = {0};

  /** DAC Initialization
  */
  hdac2.Instance = DAC2;
  if (HAL_DAC_Init(&hdac2) != HAL_OK)
  {
    Error_Handler();
  }
  /** DAC channel OUT1 config
  */
  sConfig.DAC_Trigger = DAC_TRIGGER_T6_TRGO;
  sConfig.DAC_OutputBuffer = DAC_OUTPUTBUFFER_ENABLE;
  if (HAL_DAC_ConfigChannel(&hdac2, &sConfig, DAC_CHANNEL_1) != HAL_OK)
  {
    Error_Handler();
  }

}

static void MX_RTC_Init(void)
{

  RTC_TimeTypeDef sTime = {0};
  RTC_DateTypeDef sDate = {0};
  RTC_AlarmTypeDef sAlarm = {0};

  /** Initialize RTC Only
  */
  hrtc.Instance = RTC;
  hrtc.Init.HourFormat = RTC_HOURFORMAT_24;
  hrtc.Init.AsynchPrediv = 127;
  hrtc.Init.SynchPrediv = 255;
  hrtc.Init.OutPut = RTC_OUTPUT_DISABLE;
  hrtc.Init.OutPutPolarity = RTC_OUTPUT_POLARITY_HIGH;
  hrtc.Init.OutPutType = RTC_OUTPUT_TYPE_OPENDRAIN;
  if (HAL_RTC_Init(&hrtc) != HAL_OK)
  {
    Error_Handler();
  }

  /** Initialize RTC and set the Time and Date
  */
  sTime.Hours = 0;
  sTime.Minutes = 0;
  sTime.Seconds = 0;
  sTime.DayLightSaving = RTC_DAYLIGHTSAVING_NONE;
  sTime.StoreOperation = RTC_STOREOPERATION_RESET;
  if (HAL_RTC_SetTime(&hrtc, &sTime, RTC_FORMAT_BIN) != HAL_OK)
  {
    Error_Handler();
  }
  sDate.WeekDay = RTC_WEEKDAY_MONDAY;
  sDate.Month = RTC_MONTH_JANUARY;
  sDate.Date = 1;
  sDate.Year = 0;

  if (HAL_RTC_SetDate(&hrtc, &sDate, RTC_FORMAT_BIN) != HAL_OK)
  {
    Error_Handler();
  }
  /** Enable the Alarm A
  */
  sAlarm.AlarmTime.Hours = 0;
  sAlarm.AlarmTime.Minutes = 0;
  sAlarm.AlarmTime.Seconds = 0;
  sAlarm.AlarmTime.SubSeconds = 0;
  sAlarm.AlarmTime.DayLightSaving = RTC_DAYLIGHTSAVING_NONE;
  sAlarm.AlarmTime.StoreOperation = RTC_STOREOPERATION_RESET;
  sAlarm.AlarmMask = RTC_ALARMMASK_NONE;
  sAlarm.AlarmSubSecondMask = RTC_ALARMSUBSECONDMASK_ALL;
  sAlarm.AlarmDateWeekDaySel = RTC_ALARMDATEWEEKDAYSEL_DATE;
  sAlarm.AlarmDateWeekDay = 1;
  sAlarm.Alarm = RTC_ALARM_A;
  if (HAL_RTC_SetAlarm(&hrtc, &sAlarm, RTC_FORMAT_BIN) != HAL_OK)
  {
    Error_Handler();
  }
  /** Enable the Alarm B
  */
  sAlarm.AlarmDateWeekDaySel = RTC_ALARMDATEWEEKDAYSEL_WEEKDAY;
  sAlarm.Alarm = RTC_ALARM_B;

}

static void MX_SDADC1_Init(void)
{

  SDADC_ConfParamTypeDef ConfParamStruct = {0};

  /** Configure the SDADC low power mode, fast conversion mode,
  slow clock mode and SDADC1 reference voltage
  */
  hsdadc1.Instance = SDADC1;
  hsdadc1.Init.IdleLowPowerMode = SDADC_LOWPOWER_NONE;
  hsdadc1.Init.FastConversionMode = SDADC_FAST_CONV_DISABLE;
  hsdadc1.Init.SlowClockMode = SDADC_SLOW_CLOCK_DISABLE;
  hsdadc1.Init.ReferenceVoltage = SDADC_VREF_EXT;
  hsdadc1.InjectedTrigger = SDADC_EXTERNAL_TRIGGER;
  hsdadc1.ExtTriggerEdge = SDADC_EXT_TRIG_RISING_EDGE;
  if (HAL_SDADC_Init(&hsdadc1) != HAL_OK)
  {
    Error_Handler();
  }
  /** Configure the Injected Mode
  */
  if (HAL_SDADC_SelectInjectedDelay(&hsdadc1, SDADC_INJECTED_DELAY_NONE) != HAL_OK)
  {
    Error_Handler();
  }
  if (HAL_SDADC_SelectInjectedExtTrigger(&hsdadc1, SDADC_EXT_TRIG_TIM13_CC1, SDADC_EXT_TRIG_RISING_EDGE) != HAL_OK)
  {
    Error_Handler();
  }
  if (HAL_SDADC_SelectInjectedTrigger(&hsdadc1, SDADC_EXTERNAL_TRIGGER) != HAL_OK)
  {
    Error_Handler();
  }
  if (HAL_SDADC_InjectedConfigChannel(&hsdadc1, SDADC_CHANNEL_0|SDADC_CHANNEL_1
                              |SDADC_CHANNEL_2|SDADC_CHANNEL_3
                              |SDADC_CHANNEL_4|SDADC_CHANNEL_5
                              |SDADC_CHANNEL_6|SDADC_CHANNEL_7
                              |SDADC_CHANNEL_8, SDADC_CONTINUOUS_CONV_ON) != HAL_OK)
  {
    Error_Handler();
  }
  /** Set parameters for SDADC configuration 0 Register
  */
  ConfParamStruct.InputMode = SDADC_INPUT_MODE_SE_ZERO_REFERENCE;
  ConfParamStruct.Gain = SDADC_GAIN_1;
  ConfParamStruct.CommonMode = SDADC_COMMON_MODE_VSSA;
  ConfParamStruct.Offset = 0;
  if (HAL_SDADC_PrepareChannelConfig(&hsdadc1, SDADC_CONF_INDEX_0, &ConfParamStruct) != HAL_OK)
  {
    Error_Handler();
  }
  /** Set parameters for SDADC configuration 1 Register
  */
  if (HAL_SDADC_PrepareChannelConfig(&hsdadc1, SDADC_CONF_INDEX_1, &ConfParamStruct) != HAL_OK)
  {
    Error_Handler();
  }
  /** Set parameters for SDADC configuration 2 Register
  */
  if (HAL_SDADC_PrepareChannelConfig(&hsdadc1, SDADC_CONF_INDEX_2, &ConfParamStruct) != HAL_OK)
  {
    Error_Handler();
  }
  /** Configure the Injected Channel
  */
  if (HAL_SDADC_AssociateChannelConfig(&hsdadc1, SDADC_CHANNEL_0, SDADC_CONF_INDEX_0) != HAL_OK)
  {
    Error_Handler();
  }
  /** Configure the Injected Channel
  */
  if (HAL_SDADC_AssociateChannelConfig(&hsdadc1, SDADC_CHANNEL_1, SDADC_CONF_INDEX_0) != HAL_OK)
  {
    Error_Handler();
  }
  /** Configure the Injected Channel
  */
  if (HAL_SDADC_AssociateChannelConfig(&hsdadc1, SDADC_CHANNEL_2, SDADC_CONF_INDEX_0) != HAL_OK)
  {
    Error_Handler();
  }
  /** Configure the Injected Channel
  */
  if (HAL_SDADC_AssociateChannelConfig(&hsdadc1, SDADC_CHANNEL_3, SDADC_CONF_INDEX_1) != HAL_OK)
  {
    Error_Handler();
  }
  /** Configure the Injected Channel
  */
  if (HAL_SDADC_AssociateChannelConfig(&hsdadc1, SDADC_CHANNEL_4, SDADC_CONF_INDEX_1) != HAL_OK)
  {
    Error_Handler();
  }
  /** Configure the Injected Channel
  */
  if (HAL_SDADC_AssociateChannelConfig(&hsdadc1, SDADC_CHANNEL_5, SDADC_CONF_INDEX_1) != HAL_OK)
  {
    Error_Handler();
  }
  /** Configure the Injected Channel
  */
  if (HAL_SDADC_AssociateChannelConfig(&hsdadc1, SDADC_CHANNEL_6, SDADC_CONF_INDEX_2) != HAL_OK)
  {
    Error_Handler();
  }
  /** Configure the Injected Channel
  */
  if (HAL_SDADC_AssociateChannelConfig(&hsdadc1, SDADC_CHANNEL_7, SDADC_CONF_INDEX_2) != HAL_OK)
  {
    Error_Handler();
  }
  /** Configure the Injected Channel
  */
  if (HAL_SDADC_AssociateChannelConfig(&hsdadc1, SDADC_CHANNEL_8, SDADC_CONF_INDEX_2) != HAL_OK)
  {
    Error_Handler();
  }

}

static void MX_SDADC2_Init(void)
{

  SDADC_ConfParamTypeDef ConfParamStruct = {0};

  /** Configure the SDADC low power mode, fast conversion mode,
  slow clock mode and SDADC1 reference voltage
  */
  hsdadc2.Instance = SDADC2;
  hsdadc2.Init.IdleLowPowerMode = SDADC_LOWPOWER_NONE;
  hsdadc2.Init.FastConversionMode = SDADC_FAST_CONV_DISABLE;
  hsdadc2.Init.SlowClockMode = SDADC_SLOW_CLOCK_DISABLE;
  hsdadc2.Init.ReferenceVoltage = SDADC_VREF_EXT;
  hsdadc2.InjectedTrigger = SDADC_EXTERNAL_TRIGGER;
  hsdadc2.ExtTriggerEdge = SDADC_EXT_TRIG_RISING_EDGE;
  if (HAL_SDADC_Init(&hsdadc2) != HAL_OK)
  {
    Error_Handler();
  }
  /** Configure the Injected Mode
  */
  if (HAL_SDADC_SelectInjectedDelay(&hsdadc2, SDADC_INJECTED_DELAY_NONE) != HAL_OK)
  {
    Error_Handler();
  }
  if (HAL_SDADC_SelectInjectedExtTrigger(&hsdadc2, SDADC_EXT_TRIG_TIM12_CC1, SDADC_EXT_TRIG_RISING_EDGE) != HAL_OK)
  {
    Error_Handler();
  }
  if (HAL_SDADC_SelectInjectedTrigger(&hsdadc2, SDADC_EXTERNAL_TRIGGER) != HAL_OK)
  {
    Error_Handler();
  }
  if (HAL_SDADC_InjectedConfigChannel(&hsdadc2, SDADC_CHANNEL_0|SDADC_CHANNEL_1
                              |SDADC_CHANNEL_2, SDADC_CONTINUOUS_CONV_ON) != HAL_OK)
  {
    Error_Handler();
  }
  /** Set parameters for SDADC configuration 0 Register
  */
  ConfParamStruct.InputMode = SDADC_INPUT_MODE_SE_ZERO_REFERENCE;
  ConfParamStruct.Gain = SDADC_GAIN_1;
  ConfParamStruct.CommonMode = SDADC_COMMON_MODE_VSSA;
  ConfParamStruct.Offset = 0;
  if (HAL_SDADC_PrepareChannelConfig(&hsdadc2, SDADC_CONF_INDEX_0, &ConfParamStruct) != HAL_OK)
  {
    Error_Handler();
  }
  /** Set parameters for SDADC configuration 1 Register
  */
  if (HAL_SDADC_PrepareChannelConfig(&hsdadc2, SDADC_CONF_INDEX_1, &ConfParamStruct) != HAL_OK)
  {
    Error_Handler();
  }
  /** Set parameters for SDADC configuration 2 Register
  */
  if (HAL_SDADC_PrepareChannelConfig(&hsdadc2, SDADC_CONF_INDEX_2, &ConfParamStruct) != HAL_OK)
  {
    Error_Handler();
  }
  /** Configure the Injected Channel
  */
  if (HAL_SDADC_AssociateChannelConfig(&hsdadc2, SDADC_CHANNEL_0, SDADC_CONF_INDEX_0) != HAL_OK)
  {
    Error_Handler();
  }
  /** Configure the Injected Channel
  */
  if (HAL_SDADC_AssociateChannelConfig(&hsdadc2, SDADC_CHANNEL_1, SDADC_CONF_INDEX_1) != HAL_OK)
  {
    Error_Handler();
  }
  /** Configure the Injected Channel
  */
  if (HAL_SDADC_AssociateChannelConfig(&hsdadc2, SDADC_CHANNEL_2, SDADC_CONF_INDEX_2) != HAL_OK)
  {
    Error_Handler();
  }

}

static void MX_SDADC3_Init(void)
{

  SDADC_ConfParamTypeDef ConfParamStruct = {0};

  /** Configure the SDADC low power mode, fast conversion mode,
  slow clock mode and SDADC1 reference voltage
  */
  hsdadc3.Instance = SDADC3;
  hsdadc3.Init.IdleLowPowerMode = SDADC_LOWPOWER_NONE;
  hsdadc3.Init.FastConversionMode = SDADC_FAST_CONV_DISABLE;
  hsdadc3.Init.SlowClockMode = SDADC_SLOW_CLOCK_DISABLE;
  hsdadc3.Init.ReferenceVoltage = SDADC_VREF_EXT;
  hsdadc3.InjectedTrigger = SDADC_EXTERNAL_TRIGGER;
  hsdadc3.ExtTriggerEdge = SDADC_EXT_TRIG_RISING_EDGE;
  if (HAL_SDADC_Init(&hsdadc3) != HAL_OK)
  {
    Error_Handler();
  }
  /** Configure the Injected Mode
  */
  if (HAL_SDADC_SelectInjectedDelay(&hsdadc3, SDADC_INJECTED_DELAY_NONE) != HAL_OK)
  {
    Error_Handler();
  }
  if (HAL_SDADC_SelectInjectedExtTrigger(&hsdadc3, SDADC_EXT_TRIG_TIM12_CC2, SDADC_EXT_TRIG_RISING_EDGE) != HAL_OK)
  {
    Error_Handler();
  }
  if (HAL_SDADC_SelectInjectedTrigger(&hsdadc3, SDADC_EXTERNAL_TRIGGER) != HAL_OK)
  {
    Error_Handler();
  }
  if (HAL_SDADC_InjectedConfigChannel(&hsdadc3, SDADC_CHANNEL_0|SDADC_CHANNEL_2
                              |SDADC_CHANNEL_4|SDADC_CHANNEL_6
                              |SDADC_CHANNEL_8, SDADC_CONTINUOUS_CONV_ON) != HAL_OK)
  {
    Error_Handler();
  }
  /** Set parameters for SDADC configuration 0 Register
  */
  ConfParamStruct.InputMode = SDADC_INPUT_MODE_DIFF;
  ConfParamStruct.Gain = SDADC_GAIN_1;
  ConfParamStruct.CommonMode = SDADC_COMMON_MODE_VSSA;
  ConfParamStruct.Offset = 0;
  if (HAL_SDADC_PrepareChannelConfig(&hsdadc3, SDADC_CONF_INDEX_0, &ConfParamStruct) != HAL_OK)
  {
    Error_Handler();
  }
  /** Set parameters for SDADC configuration 1 Register
  */
  if (HAL_SDADC_PrepareChannelConfig(&hsdadc3, SDADC_CONF_INDEX_1, &ConfParamStruct) != HAL_OK)
  {
    Error_Handler();
  }
  /** Set parameters for SDADC configuration 2 Register
  */
  if (HAL_SDADC_PrepareChannelConfig(&hsdadc3, SDADC_CONF_INDEX_2, &ConfParamStruct) != HAL_OK)
  {
    Error_Handler();
  }
  /** Configure the Injected Channel
  */
  if (HAL_SDADC_AssociateChannelConfig(&hsdadc3, SDADC_CHANNEL_0, SDADC_CONF_INDEX_0) != HAL_OK)
  {
    Error_Handler();
  }
  /** Configure the Injected Channel
  */
  if (HAL_SDADC_AssociateChannelConfig(&hsdadc3, SDADC_CHANNEL_2, SDADC_CONF_INDEX_0) != HAL_OK)
  {
    Error_Handler();
  }
  /** Configure the Injected Channel
  */
  if (HAL_SDADC_AssociateChannelConfig(&hsdadc3, SDADC_CHANNEL_4, SDADC_CONF_INDEX_1) != HAL_OK)
  {
    Error_Handler();
  }
  /** Configure the Injected Channel
  */
  if (HAL_SDADC_AssociateChannelConfig(&hsdadc3, SDADC_CHANNEL_6, SDADC_CONF_INDEX_1) != HAL_OK)
  {
    Error_Handler();
  }
  /** Configure the Injected Channel
  */
  if (HAL_SDADC_AssociateChannelConfig(&hsdadc3, SDADC_CHANNEL_8, SDADC_CONF_INDEX_2) != HAL_OK)
  {
    Error_Handler();
  }

}

static void MX_SPI1_Init(void)
{

  /* SPI1 parameter configuration*/
  hspi1.Instance = SPI1;
  hspi1.Init.Mode = SPI_MODE_MASTER;
  hspi1.Init.Direction = SPI_DIRECTION_2LINES;
  hspi1.Init.DataSize = SPI_DATASIZE_8BIT;
  hspi1.Init.CLKPolarity = SPI_POLARITY_LOW;
  hspi1.Init.CLKPhase = SPI_PHASE_1EDGE;
  hspi1.Init.NSS = SPI_NSS_SOFT;
  hspi1.Init.BaudRatePrescaler = SPI_BAUDRATEPRESCALER_4;
  hspi1.Init.FirstBit = SPI_FIRSTBIT_MSB;
  hspi1.Init.TIMode = SPI_TIMODE_DISABLE;
  hspi1.Init.CRCCalculation = SPI_CRCCALCULATION_DISABLE;
  hspi1.Init.CRCPolynomial = 7;
  hspi1.Init.CRCLength = SPI_CRC_LENGTH_DATASIZE;
  hspi1.Init.NSSPMode = SPI_NSS_PULSE_ENABLE;
  if (HAL_SPI_Init(&hspi1) != HAL_OK)
  {
    Error_Handler();
  }

}

static void MX_SPI2_Init(void)
{

  /* SPI2 parameter configuration*/
  hspi2.Instance = SPI2;
  hspi2.Init.Mode = SPI_MODE_MASTER;
  hspi2.Init.Direction = SPI_DIRECTION_2LINES;
  hspi2.Init.DataSize = SPI_DATASIZE_8BIT;
  hspi2.Init.CLKPolarity = SPI_POLARITY_LOW;
  hspi2.Init.CLKPhase = SPI_PHASE_1EDGE;
  hspi2.Init.NSS = SPI_NSS_SOFT;
  hspi2.Init.BaudRatePrescaler = SPI_BAUDRATEPRESCALER_256;
  hspi2.Init.FirstBit = SPI_FIRSTBIT_MSB;
  hspi2.Init.TIMode = SPI_TIMODE_DISABLE;
  hspi2.Init.CRCCalculation = SPI_CRCCALCULATION_DISABLE;
  hspi2.Init.CRCPolynomial = 7;
  hspi2.Init.CRCLength = SPI_CRC_LENGTH_DATASIZE;
  hspi2.Init.NSSPMode = SPI_NSS_PULSE_ENABLE;
  if (HAL_SPI_Init(&hspi2) != HAL_OK)
  {
    Error_Handler();
  }

}

static void MX_TIM2_Init(void)
{

  TIM_ClockConfigTypeDef sClockSourceConfig = {0};
  TIM_MasterConfigTypeDef sMasterConfig = {0};
  TIM_OC_InitTypeDef sConfigOC = {0};

  htim2.Instance = TIM2;
  htim2.Init.Prescaler = 0;
  htim2.Init.CounterMode = TIM_COUNTERMODE_UP;
  htim2.Init.Period = 0xffff;
  htim2.Init.ClockDivision = TIM_CLOCKDIVISION_DIV1;
  htim2.Init.AutoReloadPreload = TIM_AUTORELOAD_PRELOAD_DISABLE;
  if (HAL_TIM_Base_Init(&htim2) != HAL_OK)
  {
    Error_Handler();
  }
  sClockSourceConfig.ClockSource = TIM_CLOCKSOURCE_INTERNAL;
  if (HAL_TIM_ConfigClockSource(&htim2, &sClockSourceConfig) != HAL_OK)
  {
    Error_Handler();
  }
  if (HAL_TIM_PWM_Init(&htim2) != HAL_OK)
  {
    Error_Handler();
  }
  sMasterConfig.MasterOutputTrigger = TIM_TRGO_RESET;
  sMasterConfig.MasterSlaveMode = TIM_MASTERSLAVEMODE_DISABLE;
  if (HAL_TIMEx_MasterConfigSynchronization(&htim2, &sMasterConfig) != HAL_OK)
  {
    Error_Handler();
  }
  sConfigOC.OCMode = TIM_OCMODE_PWM1;
  sConfigOC.Pulse = 0;
  sConfigOC.OCPolarity = TIM_OCPOLARITY_HIGH;
  sConfigOC.OCFastMode = TIM_OCFAST_DISABLE;
  if (HAL_TIM_PWM_ConfigChannel(&htim2, &sConfigOC, TIM_CHANNEL_1) != HAL_OK)
  {
    Error_Handler();
  }
  if (HAL_TIM_PWM_ConfigChannel(&htim2, &sConfigOC, TIM_CHANNEL_2) != HAL_OK)
  {
    Error_Handler();
  }
  if (HAL_TIM_PWM_ConfigChannel(&htim2, &sConfigOC, TIM_CHANNEL_3) != HAL_OK)
  {
    Error_Handler();
  }
  if (HAL_TIM_PWM_ConfigChannel(&htim2, &sConfigOC, TIM_CHANNEL_4) != HAL_OK)
  {
    Error_Handler();
  }
  HAL_TIM_MspPostInit(&htim2);

}

static void MX_TIM4_Init(void)
{

  TIM_Encoder_InitTypeDef sConfig = {0};
  TIM_MasterConfigTypeDef sMasterConfig = {0};

  htim4.Instance = TIM4;
  htim4.Init.Prescaler = 0;
  htim4.Init.CounterMode = TIM_COUNTERMODE_UP;
  htim4.Init.Period = 65535;
  htim4.Init.ClockDivision = TIM_CLOCKDIVISION_DIV1;
  htim4.Init.AutoReloadPreload = TIM_AUTORELOAD_PRELOAD_DISABLE;
  sConfig.EncoderMode = TIM_ENCODERMODE_TI12;
  sConfig.IC1Polarity = TIM_ICPOLARITY_RISING;
  sConfig.IC1Selection = TIM_ICSELECTION_DIRECTTI;
  sConfig.IC1Prescaler = TIM_ICPSC_DIV1;
  sConfig.IC1Filter = 0;
  sConfig.IC2Polarity = TIM_ICPOLARITY_RISING;
  sConfig.IC2Selection = TIM_ICSELECTION_DIRECTTI;
  sConfig.IC2Prescaler = TIM_ICPSC_DIV1;
  sConfig.IC2Filter = 0;
  if (HAL_TIM_Encoder_Init(&htim4, &sConfig) != HAL_OK)
  {
    Error_Handler();
  }
  sMasterConfig.MasterOutputTrigger = TIM_TRGO_RESET;
  sMasterConfig.MasterSlaveMode = TIM_MASTERSLAVEMODE_DISABLE;
  if (HAL_TIMEx_MasterConfigSynchronization(&htim4, &sMasterConfig) != HAL_OK)
  {
    Error_Handler();
  }

}

static void MX_TIM5_Init(void)
{

  TIM_ClockConfigTypeDef sClockSourceConfig = {0};
  TIM_MasterConfigTypeDef sMasterConfig = {0};
  TIM_OC_InitTypeDef sConfigOC = {0};

  htim5.Instance = TIM5;
  htim5.Init.Prescaler = 0;
  htim5.Init.CounterMode = TIM_COUNTERMODE_UP;
  htim5.Init.Period = 0xffff;
  htim5.Init.ClockDivision = TIM_CLOCKDIVISION_DIV1;
  htim5.Init.AutoReloadPreload = TIM_AUTORELOAD_PRELOAD_DISABLE;
  if (HAL_TIM_Base_Init(&htim5) != HAL_OK)
  {
    Error_Handler();
  }
  sClockSourceConfig.ClockSource = TIM_CLOCKSOURCE_INTERNAL;
  if (HAL_TIM_ConfigClockSource(&htim5, &sClockSourceConfig) != HAL_OK)
  {
    Error_Handler();
  }
  if (HAL_TIM_PWM_Init(&htim5) != HAL_OK)
  {
    Error_Handler();
  }
  sMasterConfig.MasterOutputTrigger = TIM_TRGO_RESET;
  sMasterConfig.MasterSlaveMode = TIM_MASTERSLAVEMODE_DISABLE;
  if (HAL_TIMEx_MasterConfigSynchronization(&htim5, &sMasterConfig) != HAL_OK)
  {
    Error_Handler();
  }
  sConfigOC.OCMode = TIM_OCMODE_PWM1;
  sConfigOC.Pulse = 0;
  sConfigOC.OCPolarity = TIM_OCPOLARITY_HIGH;
  sConfigOC.OCFastMode = TIM_OCFAST_DISABLE;
  if (HAL_TIM_PWM_ConfigChannel(&htim5, &sConfigOC, TIM_CHANNEL_1) != HAL_OK)
  {
    Error_Handler();
  }
  if (HAL_TIM_PWM_ConfigChannel(&htim5, &sConfigOC, TIM_CHANNEL_2) != HAL_OK)
  {
    Error_Handler();
  }
  if (HAL_TIM_PWM_ConfigChannel(&htim5, &sConfigOC, TIM_CHANNEL_3) != HAL_OK)
  {
    Error_Handler();
  }
  if (HAL_TIM_PWM_ConfigChannel(&htim5, &sConfigOC, TIM_CHANNEL_4) != HAL_OK)
  {
    Error_Handler();
  }
  HAL_TIM_MspPostInit(&htim5);

}

static void MX_TIM6_Init(void)
{

  TIM_MasterConfigTypeDef sMasterConfig = {0};

  htim6.Instance = TIM6;
  htim6.Init.Prescaler = 99;
  htim6.Init.CounterMode = TIM_COUNTERMODE_UP;
  htim6.Init.Period = 0xbb80;
  htim6.Init.AutoReloadPreload = TIM_AUTORELOAD_PRELOAD_DISABLE;
  if (HAL_TIM_Base_Init(&htim6) != HAL_OK)
  {
    Error_Handler();
  }
  sMasterConfig.MasterOutputTrigger = TIM_TRGO_UPDATE;
  sMasterConfig.MasterSlaveMode = TIM_MASTERSLAVEMODE_DISABLE;
  if (HAL_TIMEx_MasterConfigSynchronization(&htim6, &sMasterConfig) != HAL_OK)
  {
    Error_Handler();
  }

}

static void MX_TIM12_Init(void)
{

  TIM_ClockConfigTypeDef sClockSourceConfig = {0};
  TIM_OC_InitTypeDef sConfigOC = {0};

  htim12.Instance = TIM12;
  htim12.Init.Prescaler = 0;
  htim12.Init.CounterMode = TIM_COUNTERMODE_UP;
  htim12.Init.Period = 0xbb80;
  htim12.Init.ClockDivision = TIM_CLOCKDIVISION_DIV1;
  htim12.Init.AutoReloadPreload = TIM_AUTORELOAD_PRELOAD_DISABLE;
  if (HAL_TIM_Base_Init(&htim12) != HAL_OK)
  {
    Error_Handler();
  }
  sClockSourceConfig.ClockSource = TIM_CLOCKSOURCE_INTERNAL;
  if (HAL_TIM_ConfigClockSource(&htim12, &sClockSourceConfig) != HAL_OK)
  {
    Error_Handler();
  }
  if (HAL_TIM_OC_Init(&htim12) != HAL_OK)
  {
    Error_Handler();
  }
  sConfigOC.OCMode = TIM_OCMODE_TOGGLE;
  sConfigOC.Pulse = 0;
  sConfigOC.OCPolarity = TIM_OCPOLARITY_HIGH;
  sConfigOC.OCFastMode = TIM_OCFAST_DISABLE;
  if (HAL_TIM_OC_ConfigChannel(&htim12, &sConfigOC, TIM_CHANNEL_1) != HAL_OK)
  {
    Error_Handler();
  }
  sConfigOC.OCMode = TIM_OCMODE_TIMING;
  if (HAL_TIM_OC_ConfigChannel(&htim12, &sConfigOC, TIM_CHANNEL_2) != HAL_OK)
  {
    Error_Handler();
  }

}

static void MX_TIM13_Init(void)
{

  TIM_OC_InitTypeDef sConfigOC = {0};

  htim13.Instance = TIM13;
  htim13.Init.Prescaler = 0;
  htim13.Init.CounterMode = TIM_COUNTERMODE_UP;
  htim13.Init.Period = 0xbb80;
  htim13.Init.ClockDivision = TIM_CLOCKDIVISION_DIV1;
  htim13.Init.AutoReloadPreload = TIM_AUTORELOAD_PRELOAD_DISABLE;
  if (HAL_TIM_Base_Init(&htim13) != HAL_OK)
  {
    Error_Handler();
  }
  if (HAL_TIM_OC_Init(&htim13) != HAL_OK)
  {
    Error_Handler();
  }
  sConfigOC.OCMode = TIM_OCMODE_TOGGLE;
  sConfigOC.Pulse = 0;
  sConfigOC.OCPolarity = TIM_OCPOLARITY_HIGH;
  sConfigOC.OCFastMode = TIM_OCFAST_DISABLE;
  if (HAL_TIM_OC_ConfigChannel(&htim13, &sConfigOC, TIM_CHANNEL_1) != HAL_OK)
  {
    Error_Handler();
  }

}

static void MX_TIM16_Init(void)
{

  TIM_IC_InitTypeDef sConfigIC = {0};

  htim16.Instance = TIM16;
  htim16.Init.Prescaler = 4799;
  htim16.Init.CounterMode = TIM_COUNTERMODE_UP;
  htim16.Init.Period = 0xffff;
  htim16.Init.ClockDivision = TIM_CLOCKDIVISION_DIV1;
  htim16.Init.RepetitionCounter = 0;
  htim16.Init.AutoReloadPreload = TIM_AUTORELOAD_PRELOAD_DISABLE;
  if (HAL_TIM_Base_Init(&htim16) != HAL_OK)
  {
    Error_Handler();
  }
  if (HAL_TIM_IC_Init(&htim16) != HAL_OK)
  {
    Error_Handler();
  }
  sConfigIC.ICPolarity = TIM_INPUTCHANNELPOLARITY_RISING;
  sConfigIC.ICSelection = TIM_ICSELECTION_DIRECTTI;
  sConfigIC.ICPrescaler = TIM_ICPSC_DIV1;
  sConfigIC.ICFilter = 0;
  if (HAL_TIM_IC_ConfigChannel(&htim16, &sConfigIC, TIM_CHANNEL_1) != HAL_OK)
  {
    Error_Handler();
  }

}

static void MX_TIM17_Init(void)
{

  TIM_IC_InitTypeDef sConfigIC = {0};

  htim17.Instance = TIM17;
  htim17.Init.Prescaler = 4799;
  htim17.Init.CounterMode = TIM_COUNTERMODE_UP;
  htim17.Init.Period = 0xffff;
  htim17.Init.ClockDivision = TIM_CLOCKDIVISION_DIV1;
  htim17.Init.RepetitionCounter = 0;
  htim17.Init.AutoReloadPreload = TIM_AUTORELOAD_PRELOAD_DISABLE;
  if (HAL_TIM_Base_Init(&htim17) != HAL_OK)
  {
    Error_Handler();
  }
  if (HAL_TIM_IC_Init(&htim17) != HAL_OK)
  {
    Error_Handler();
  }
  sConfigIC.ICPolarity = TIM_INPUTCHANNELPOLARITY_RISING;
  sConfigIC.ICSelection = TIM_ICSELECTION_DIRECTTI;
  sConfigIC.ICPrescaler = TIM_ICPSC_DIV1;
  sConfigIC.ICFilter = 0;
  if (HAL_TIM_IC_ConfigChannel(&htim17, &sConfigIC, TIM_CHANNEL_1) != HAL_OK)
  {
    Error_Handler();
  }

}

static void MX_TIM19_Init(void)
{

  TIM_Encoder_InitTypeDef sConfig = {0};
  TIM_MasterConfigTypeDef sMasterConfig = {0};

  htim19.Instance = TIM19;
  htim19.Init.Prescaler = 0;
  htim19.Init.CounterMode = TIM_COUNTERMODE_UP;
  htim19.Init.Period = 65535;
  htim19.Init.ClockDivision = TIM_CLOCKDIVISION_DIV1;
  htim19.Init.AutoReloadPreload = TIM_AUTORELOAD_PRELOAD_DISABLE;
  sConfig.EncoderMode = TIM_ENCODERMODE_TI12;
  sConfig.IC1Polarity = TIM_ICPOLARITY_RISING;
  sConfig.IC1Selection = TIM_ICSELECTION_DIRECTTI;
  sConfig.IC1Prescaler = TIM_ICPSC_DIV1;
  sConfig.IC1Filter = 0;
  sConfig.IC2Polarity = TIM_ICPOLARITY_RISING;
  sConfig.IC2Selection = TIM_ICSELECTION_DIRECTTI;
  sConfig.IC2Prescaler = TIM_ICPSC_DIV1;
  sConfig.IC2Filter = 0;
  if (HAL_TIM_Encoder_Init(&htim19, &sConfig) != HAL_OK)
  {
    Error_Handler();
  }
  sMasterConfig.MasterOutputTrigger = TIM_TRGO_RESET;
  sMasterConfig.MasterSlaveMode = TIM_MASTERSLAVEMODE_DISABLE;
  if (HAL_TIMEx_MasterConfigSynchronization(&htim19, &sMasterConfig) != HAL_OK)
  {
    Error_Handler();
  }

}

static void MX_USART1_UART_Init(void)
{

  huart1.Instance = USART1;
  huart1.Init.BaudRate = 38400;
  huart1.Init.WordLength = UART_WORDLENGTH_8B;
  huart1.Init.StopBits = UART_STOPBITS_1;
  huart1.Init.Parity = UART_PARITY_NONE;
  huart1.Init.Mode = UART_MODE_TX_RX;
  huart1.Init.HwFlowCtl = UART_HWCONTROL_NONE;
  huart1.Init.OverSampling = UART_OVERSAMPLING_16;
  huart1.Init.OneBitSampling = UART_ONE_BIT_SAMPLE_DISABLE;
  huart1.AdvancedInit.AdvFeatureInit = UART_ADVFEATURE_NO_INIT;
  if (HAL_UART_Init(&huart1) != HAL_OK)
  {
    Error_Handler();
  }

}

static void MX_DMA_Init(void)
{

  /* DMA controller clock enable */
  __HAL_RCC_DMA1_CLK_ENABLE();
  __HAL_RCC_DMA2_CLK_ENABLE();

  /* DMA interrupt init */
  /* DMA1_Channel1_IRQn interrupt configuration */
  HAL_NVIC_SetPriority(DMA1_Channel1_IRQn, 0, 0);
  HAL_NVIC_EnableIRQ(DMA1_Channel1_IRQn);
  /* DMA1_Channel3_IRQn interrupt configuration */
  HAL_NVIC_SetPriority(DMA1_Channel3_IRQn, 0, 0);
  HAL_NVIC_EnableIRQ(DMA1_Channel3_IRQn);
  /* DMA2_Channel3_IRQn interrupt configuration */
  HAL_NVIC_SetPriority(DMA2_Channel3_IRQn, 0, 0);
  HAL_NVIC_EnableIRQ(DMA2_Channel3_IRQn);
  /* DMA2_Channel4_IRQn interrupt configuration */
  HAL_NVIC_SetPriority(DMA2_Channel4_IRQn, 0, 0);
  HAL_NVIC_EnableIRQ(DMA2_Channel4_IRQn);
  /* DMA2_Channel5_IRQn interrupt configuration */
  HAL_NVIC_SetPriority(DMA2_Channel5_IRQn, 0, 0);
  HAL_NVIC_EnableIRQ(DMA2_Channel5_IRQn);

}

static void MX_GPIO_Init(void)
{
  GPIO_InitTypeDef GPIO_InitStruct = {0};

  /* GPIO Ports Clock Enable */
  __HAL_RCC_GPIOE_CLK_ENABLE();
  __HAL_RCC_GPIOC_CLK_ENABLE();
  __HAL_RCC_GPIOF_CLK_ENABLE();
  __HAL_RCC_GPIOA_CLK_ENABLE();
  __HAL_RCC_GPIOB_CLK_ENABLE();
  __HAL_RCC_GPIOD_CLK_ENABLE();

  /*Configure GPIO pin Output Level */
  HAL_GPIO_WritePin(CS4_GPIO_Port, CS4_Pin, GPIO_PIN_SET);

  /*Configure GPIO pin Output Level */
  HAL_GPIO_WritePin(GPIOF, CS3_Pin|LCD_RST_Pin, GPIO_PIN_RESET);

  /*Configure GPIO pin Output Level */
  HAL_GPIO_WritePin(CS0_GPIO_Port, CS0_Pin, GPIO_PIN_SET);

  /*Configure GPIO pin Output Level */
  HAL_GPIO_WritePin(GPIOC, CS1_Pin|CS2_Pin|TS_CS_Pin, GPIO_PIN_SET);

  /*Configure GPIO pin Output Level */
  HAL_GPIO_WritePin(CS5_GPIO_Port, CS5_Pin, GPIO_PIN_SET);

  /*Configure GPIO pin Output Level */
  HAL_GPIO_WritePin(LCD_DC_GPIO_Port, LCD_DC_Pin, GPIO_PIN_RESET);

  /*Configure GPIO pin Output Level */
  HAL_GPIO_WritePin(GPIOD, LCD_CS_Pin|SD_CS_Pin, GPIO_PIN_SET);

  /*Configure GPIO pin Output Level */
  HAL_GPIO_WritePin(GPIOD, LED0_Pin|LED1_Pin|LED2_Pin, GPIO_PIN_RESET);

  /*Configure GPIO pin Output Level */
  HAL_GPIO_WritePin(GPIOB, LED3_Pin|LED4_Pin, GPIO_PIN_RESET);

  /*Configure GPIO pins : DI0_Pin DI1_Pin DI2_Pin DI3_Pin
                           DI4_Pin */
  GPIO_InitStruct.Pin = DI0_Pin|DI1_Pin|DI2_Pin|DI3_Pin
                          |DI4_Pin;
  GPIO_InitStruct.Mode = GPIO_MODE_INPUT;
  GPIO_InitStruct.Pull = GPIO_NOPULL;
  HAL_GPIO_Init(GPIOE, &GPIO_InitStruct);

  /*Configure GPIO pins : DI5_Pin STOP_LOGGING_CONTROL_Pin */
  GPIO_InitStruct.Pin = DI5_Pin|STOP_LOGGING_CONTROL_Pin;
  GPIO_InitStruct.Mode = GPIO_MODE_INPUT;
  GPIO_InitStruct.Pull = GPIO_NOPULL;
  HAL_GPIO_Init(GPIOC, &GPIO_InitStruct);

  /*Configure GPIO pins : DI6_Pin DI7_Pin */
  GPIO_InitStruct.Pin = DI6_Pin|DI7_Pin;
  GPIO_InitStruct.Mode = GPIO_MODE_INPUT;
  GPIO_InitStruct.Pull = GPIO_NOPULL;
  HAL_GPIO_Init(GPIOF, &GPIO_InitStruct);

  /*Configure GPIO pin : CS4_Pin */
  GPIO_InitStruct.Pin = CS4_Pin;
  GPIO_InitStruct.Mode = GPIO_MODE_OUTPUT_PP;
  GPIO_InitStruct.Pull = GPIO_PULLUP;
  GPIO_InitStruct.Speed = GPIO_SPEED_FREQ_LOW;
  HAL_GPIO_Init(CS4_GPIO_Port, &GPIO_InitStruct);

  /*Configure GPIO pins : CS3_Pin LCD_RST_Pin */
  GPIO_InitStruct.Pin = CS3_Pin|LCD_RST_Pin;
  GPIO_InitStruct.Mode = GPIO_MODE_OUTPUT_PP;
  GPIO_InitStruct.Pull = GPIO_NOPULL;
  GPIO_InitStruct.Speed = GPIO_SPEED_FREQ_LOW;
  HAL_GPIO_Init(GPIOF, &GPIO_InitStruct);

  /*Configure GPIO pin : CS0_Pin */
  GPIO_InitStruct.Pin = CS0_Pin;
  GPIO_InitStruct.Mode = GPIO_MODE_OUTPUT_PP;
  GPIO_InitStruct.Pull = GPIO_PULLUP;
  GPIO_InitStruct.Speed = GPIO_SPEED_FREQ_LOW;
  HAL_GPIO_Init(CS0_GPIO_Port, &GPIO_InitStruct);

  /*Configure GPIO pins : CS1_Pin CS2_Pin TS_CS_Pin */
  GPIO_InitStruct.Pin = CS1_Pin|CS2_Pin|TS_CS_Pin;
  GPIO_InitStruct.Mode = GPIO_MODE_OUTPUT_PP;
  GPIO_InitStruct.Pull = GPIO_PULLUP;
  GPIO_InitStruct.Speed = GPIO_SPEED_FREQ_LOW;
  HAL_GPIO_Init(GPIOC, &GPIO_InitStruct);

  /*Configure GPIO pin : CS5_Pin */
  GPIO_InitStruct.Pin = CS5_Pin;
  GPIO_InitStruct.Mode = GPIO_MODE_OUTPUT_PP;
  GPIO_InitStruct.Pull = GPIO_PULLUP;
  GPIO_InitStruct.Speed = GPIO_SPEED_FREQ_LOW;
  HAL_GPIO_Init(CS5_GPIO_Port, &GPIO_InitStruct);

  /*Configure GPIO pin : LCD_DC_Pin */
  GPIO_InitStruct.Pin = LCD_DC_Pin;
  GPIO_InitStruct.Mode = GPIO_MODE_OUTPUT_PP;
  GPIO_InitStruct.Pull = GPIO_NOPULL;
  GPIO_InitStruct.Speed = GPIO_SPEED_FREQ_LOW;
  HAL_GPIO_Init(LCD_DC_GPIO_Port, &GPIO_InitStruct);

  /*Configure GPIO pins : LCD_CS_Pin SD_CS_Pin */
  GPIO_InitStruct.Pin = LCD_CS_Pin|SD_CS_Pin;
  GPIO_InitStruct.Mode = GPIO_MODE_OUTPUT_PP;
  GPIO_InitStruct.Pull = GPIO_PULLUP;
  GPIO_InitStruct.Speed = GPIO_SPEED_FREQ_LOW;
  HAL_GPIO_Init(GPIOD, &GPIO_InitStruct);

  /*Configure GPIO pin : TS_IRQ_Pin */
  GPIO_InitStruct.Pin = TS_IRQ_Pin;
  GPIO_InitStruct.Mode = GPIO_MODE_INPUT;
  GPIO_InitStruct.Pull = GPIO_PULLUP;
  HAL_GPIO_Init(TS_IRQ_GPIO_Port, &GPIO_InitStruct);

  /*Configure GPIO pins : LED0_Pin LED1_Pin LED2_Pin */
  GPIO_InitStruct.Pin = LED0_Pin|LED1_Pin|LED2_Pin;
  GPIO_InitStruct.Mode = GPIO_MODE_OUTPUT_PP;
  GPIO_InitStruct.Pull = GPIO_NOPULL;
  GPIO_InitStruct.Speed = GPIO_SPEED_FREQ_LOW;
  HAL_GPIO_Init(GPIOD, &GPIO_InitStruct);

  /*Configure GPIO pins : LED3_Pin LED4_Pin */
  GPIO_InitStruct.Pin = LED3_Pin|LED4_Pin;
  GPIO_InitStruct.Mode = GPIO_MODE_OUTPUT_PP;
  GPIO_InitStruct.Pull = GPIO_NOPULL;
  GPIO_InitStruct.Speed = GPIO_SPEED_FREQ_LOW;
  HAL_GPIO_Init(GPIOB, &GPIO_InitStruct);

}

void Error_Handler(void)
{
  __disable_irq();
  while (1)
  {
  }
}

/************************ (C) COPYRIGHT STMicroelectronics *****END OF FILE****/
